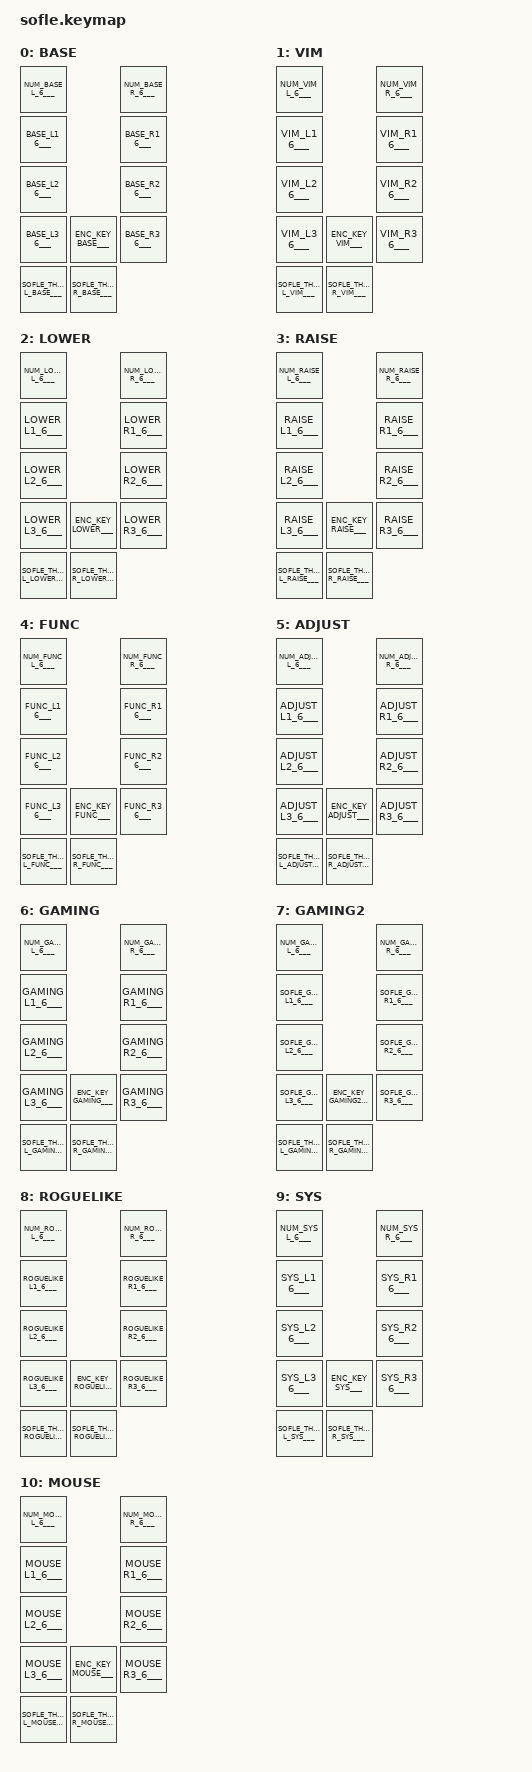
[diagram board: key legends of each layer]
// clang-format off
#include <behaviors.dtsi>
#include <dt-bindings/zmk/keys.h>
#include <dt-bindings/zmk/mouse.h>
#include "behaviors.dtsi" // before wrappers because .dtsi are fucking dumb
#include "combos.dtsi" // Shared combo definitions

/*                                      60 KEY MATRIX / LAYOUT MAPPING

  ╭────────────────────────────┬────────────────────────────╮ ╭─────────────────────────────┬─────────────────────────────╮
  │  0   1   2   3   4   5     │      6   7   8   9  10  11 │ │ LN5 LN4 LN3 LN2 LN1 LN0     │     RN0 RN1 RN2 RN3 RN4 RN5 │
  │ 12  13  14  15  16  17     │     18  19  20  21  22  23 │ │ LT5 LT4 LT3 LT2 LT1 LT0     │     RT0 RT1 RT2 RT3 RT4 RT5 │
  │ 24  25  26  27  28  29     │     30  31  32  33  34  35 │ │ LM5 LM4 LM3 LM2 LM1 LM0     │     RM0 RM1 RM2 RM3 RM4 RM5 │
  │ 36  37  38  39  40  41  42 │ 43  44  45  46  47  48  49 │ │ LB5 LB4 LB3 LB2 LB1 LB0 LEC │ REC RB0 RB1 RB2 RB3 RB4 RB5 │
  ╰───────╮ 50  51  52  53  54 │ 55  56  57  58  59 ╭───────╯ ╰───────╮ LH4 LH3 LH2 LH1 LH0 │ RH0 RH1 RH2 RH3 RH4 ╭───────╯
          ╰────────────────────┴────────────────────╯                 ╰─────────────────────┴─────────────────────╯         */

/*                      cheater map for brain farts while writing combos
  ╭────────────────────────────┬────────────────────────────╮
  │  0   1   2   3   4   5     │      6   7   8   9  10  11 │
                          NUMBER ROW
  │ 12  13  14  15  16  17     │     18  19  20  21  22  23 │
   ---   Q   W   E   R   T            Y   U   I   O   P  ---
  │ 24  25  26  27  28  29     │     30  31  32  33  34  35 │
   ---   A   S   D   F   G            H   J   K   L   ;  ---
  │ 36  37  38  39  40  41  42 │ 43  44  45  46  47  48  49 │
   ---   Z   X   C   V   B            N   M   ,   .   /  ---
  ╰───────╮ 50  51  52  53  54 │ 55  56  57  58  59 ╭───────╯
                          SOFLE THUMB KEYS
          ╰────────────────────┴────────────────────╯
*/
/ {
    combos {
        combo_hj_caps_word {
            key-positions = <30 31>;
        };
        combo_yh_num_word {
            key-positions = <30 18>;
        };
        combo_jk_esc {
            key-positions = <31 32>;
        };
        combo_lscln_ent {
            key-positions = <33 34>;
        };
        combo_fg_tab {
            key-positions = <28 29>;
        };
        combo_as_bspc {
            key-positions = <25 26>;
        };
        combo_ui_equal {
            key-positions = <19 20>;  // U + I
        };
        combo_df_underscore {
            key-positions = <27 28>;
        };
        combo_vb_space {
            key-positions = <40 41>;  // V + B
        };
        combo_cv_minus {
            key-positions = <39 40>;
        };
        combo_zx_del {
            key-positions = <37 38>;
        };
        combo_dc_assign {
            key-positions = <27 39>;
        };
        combo_gb_leader {
            key-positions = <29 41>;  // G + B
        };
        combo_kl_sqt {
            key-positions = <32 33>;
        };
        combo_jkl_dqt {
            key-positions = <31 32 33>;
        };
        combo_kl_scln_ccs {
            key-positions = <32 33 34>;
        };
        // testing [](){} auto double and move cursor inside, right hand initiation since
        // qwerty is to heavy on left hand actions and i unintentionally made my left
        // hand symbols the more common ones as well.
        combo_nm_parens {
            key-positions = <44 45>;
        };
        combo_m_comma_braces {
            key-positions = <45 46>;
        };
        combo_comma_dot_brackets {
            key-positions = <46 47>;
        };
        combo_dot_slash_ltgt {
            key-positions = <47 48>;
        };
        // Similar concept but for quotes
        combo_jm_squotes {
            key-positions = <31 45>;
        };
        combo_k_comma_dquotes {
            key-positions = <32 46>;
        };
// =====================================================================================
// GACS but for combos and row 1 instead of homerow (row 2) this is also a test, and more
// so intended for a non-HRM layer for roguelike development, as when im not on a laptop
// it is nice to hit hjkl without the games framebuffer ignoring due to timing on firmware
// based off my old vim layers from QMK, will create that in the future, its low-pri
// =====================================================================================
        combo_qw_lgui {
            key-positions = <13 14>;
        };
        combo_we_lalt {
            key-positions = <14 15>;
        };
        combo_er_lctrl {
            key-positions = <15 16>;
        };
        combo_rt_lshift {
            key-positions = <16 17>;
        };

// =====================================================================================
        // right side
        combo_yu_rshift {
            key-positions = <18 19>;
        };
        combo_ui_rctrl {
            key-positions = <19 20>;
        };
        combo_io_ralt {
            key-positions = <20 21>;
        };
        combo_op_rgui {
            key-positions = <21 22>;
        };
// =====================================================================================
// BASE-only top row combos
// =====================================================================================
        combo_qw_noteq {
            key-positions = <13 14>;  // Q + W
        };
        combo_er_repeat {
            key-positions = <15 16>;  // E + R
        };
        combo_io_colon {
            key-positions = <20 21>;  // I + O
        };
// =====================================================================================
// Three-finger layer switching combos
// =====================================================================================
        combo_return_to_base {
            key-positions = <13 14 15>;  // QWE
        };
        combo_base_to_gaming {
            key-positions = <25 26 27>;  // ASD
        };
        combo_base_to_vim {
            key-positions = <44 45 46>;  // NM,
        };
        combo_vim_to_base {
            key-positions = <44 45 46>;  // NM,
        };
        combo_gaming_to_roguelike {
            key-positions = <30 31 32>;  // HJK
        };
        combo_roguelike_to_gaming {
            key-positions = <30 31 32>;  // HJK
        };
        combo_gaming_to_gaming2 {
            key-positions = <18 19 20>;  // YUI
        };
        combo_gaming2_to_gaming {
            key-positions = <18 19 20>;  // YUI
        };
};

    keymap {

        // base, vim, lower, raise, gaming, gaming2, roguelike, sys, mouse
        compatible = "zmk,keymap";

        base {
            display-name = "BASE";
            bindings = <
                  ___NUM_BASE_L_6___                   ___NUM_BASE_R_6___
                  ___BASE_L1_6___                    ___BASE_R1_6___
                  ___BASE_L2_6___                    ___BASE_R2_6___
                  ___BASE_L3_6___ ___ENC_KEY_BASE___ ___BASE_R3_6___
                ___SOFLE_THUMBS_L_BASE___ ___SOFLE_THUMBS_R_BASE___
            >;
                 sensor-bindings = <___ENC_BASE___>;
        };

        vim {
            display-name = "VIM";
            bindings = <
                  ___NUM_VIM_L_6___                   ___NUM_VIM_R_6___
                  ___VIM_L1_6___                    ___VIM_R1_6___
                  ___VIM_L2_6___                    ___VIM_R2_6___
                  ___VIM_L3_6___ ___ENC_KEY_VIM___ ___VIM_R3_6___
                ___SOFLE_THUMBS_L_VIM___ ___SOFLE_THUMBS_R_VIM___
            >;
                 sensor-bindings = <___ENC_VIM___>;
        };

        lower {
            display-name = "LOWER";
            bindings = <
                  ___NUM_LOWER_L_6___                   ___NUM_LOWER_R_6___
                  ___LOWER_L1_6___                    ___LOWER_R1_6___
                  ___LOWER_L2_6___                    ___LOWER_R2_6___
                  ___LOWER_L3_6___ ___ENC_KEY_LOWER___ ___LOWER_R3_6___
                ___SOFLE_THUMBS_L_LOWER___ ___SOFLE_THUMBS_R_LOWER___
            >;
                 sensor-bindings = <___ENC_LOWER___>;
        };

        raise {
            display-name = "RAISE";
            bindings = <
                  ___NUM_RAISE_L_6___                   ___NUM_RAISE_R_6___
                  ___RAISE_L1_6___                    ___RAISE_R1_6___
                  ___RAISE_L2_6___                    ___RAISE_R2_6___
                  ___RAISE_L3_6___ ___ENC_KEY_RAISE___ ___RAISE_R3_6___
                ___SOFLE_THUMBS_L_RAISE___ ___SOFLE_THUMBS_R_RAISE___
            >;
                 sensor-bindings = <___ENC_RAISE___>;
        };

        func {
            display-name = "FUNC";
            bindings = <
                  ___NUM_FUNC_L_6___                   ___NUM_FUNC_R_6___
                  ___FUNC_L1_6___                    ___FUNC_R1_6___
                  ___FUNC_L2_6___                    ___FUNC_R2_6___
                  ___FUNC_L3_6___ ___ENC_KEY_FUNC___ ___FUNC_R3_6___
                ___SOFLE_THUMBS_L_FUNC___ ___SOFLE_THUMBS_R_FUNC___
            >;
                 sensor-bindings = <___ENC_FUNC___>;
        };

        adjust {
            display-name = "ADJUST";
            bindings = <
                  ___NUM_ADJUST_L_6___                   ___NUM_ADJUST_R_6___
                  ___ADJUST_L1_6___                    ___ADJUST_R1_6___
                  ___ADJUST_L2_6___                    ___ADJUST_R2_6___
                  ___ADJUST_L3_6___ ___ENC_KEY_ADJUST___ ___ADJUST_R3_6___
                ___SOFLE_THUMBS_L_ADJUST___ ___SOFLE_THUMBS_R_ADJUST___
            >;
                 sensor-bindings = <___ENC_ADJUST___>;
        };

        gaming {
            display-name = "GAMING";
            bindings = <
                  ___NUM_GAMING_L_6___                   ___NUM_GAMING_R_6___
                  ___GAMING_L1_6___                      ___GAMING_R1_6___
                  ___GAMING_L2_6___                      ___GAMING_R2_6___
                  ___GAMING_L3_6___ ___ENC_KEY_GAMING___ ___GAMING_R3_6___
                ___SOFLE_THUMBS_L_GAMING___ ___SOFLE_THUMBS_R_GAMING___
            >;
                 sensor-bindings = <___ENC_GAMING___>;
        };

        gaming2 {
            display-name = "GAMING2";
            bindings = <
                  ___NUM_GAMING2_L_6___                       ___NUM_GAMING2_R_6___
                  ___SOFLE_GAMING2_L1_6___                    ___SOFLE_GAMING2_R1_6___
                  ___SOFLE_GAMING2_L2_6___                    ___SOFLE_GAMING2_R2_6___
                  ___SOFLE_GAMING2_L3_6___ ___ENC_KEY_GAMING2___ ___SOFLE_GAMING2_R3_6___
                ___SOFLE_THUMBS_L_GAMING2___ ___SOFLE_THUMBS_R_GAMING2___
            >;
                 sensor-bindings = <___ENC_GAMING2___>;
        };

        roguelike {
            display-name = "ROGUELIKE";
            bindings = <
                  ___NUM_ROGUELIKE_L_6___                   ___NUM_ROGUELIKE_R_6___
                  ___ROGUELIKE_L1_6___                    ___ROGUELIKE_R1_6___
                  ___ROGUELIKE_L2_6___                    ___ROGUELIKE_R2_6___
                  ___ROGUELIKE_L3_6___ ___ENC_KEY_ROGUELIKE___ ___ROGUELIKE_R3_6___
                ___SOFLE_THUMBS_L_ROGUELIKE___ ___SOFLE_THUMBS_R_ROGUELIKE___
            >;
                 sensor-bindings = <___ENC_ROGUELIKE___>;
        };

        sys {
            display-name = "SYS";
            bindings = <
                  ___NUM_SYS_L_6___                   ___NUM_SYS_R_6___
                  ___SYS_L1_6___                    ___SYS_R1_6___
                  ___SYS_L2_6___                    ___SYS_R2_6___
                  ___SYS_L3_6___ ___ENC_KEY_SYS___ ___SYS_R3_6___
                ___SOFLE_THUMBS_L_SYS___ ___SOFLE_THUMBS_R_SYS___
            >;
                 sensor-bindings = <___ENC_SYS___>;
        };

        mouse {
            display-name = "MOUSE";
            bindings = <
                  ___NUM_MOUSE_L_6___                   ___NUM_MOUSE_R_6___
                  ___MOUSE_L1_6___                    ___MOUSE_R1_6___
                  ___MOUSE_L2_6___                    ___MOUSE_R2_6___
                  ___MOUSE_L3_6___ ___ENC_KEY_MOUSE___ ___MOUSE_R3_6___
                ___SOFLE_THUMBS_L_MOUSE___ ___SOFLE_THUMBS_R_MOUSE___
            >;
                 sensor-bindings = <___ENC_MOUSE___>;
        };
    };
};
